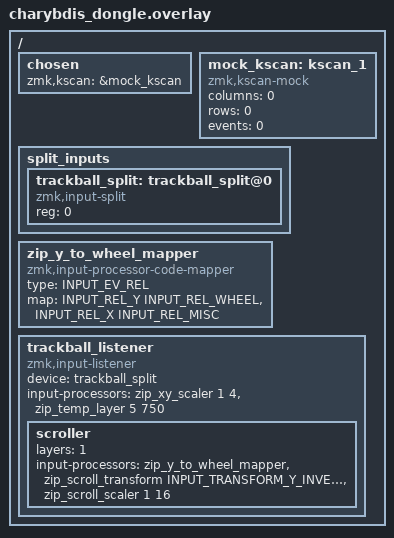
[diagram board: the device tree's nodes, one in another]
#include "charybdis.dtsi"

#include <zephyr/dt-bindings/input/input-event-codes.h>
#include <input/processors.dtsi>
#include <dt-bindings/zmk/input_transform.h>

/ {
    chosen {
        zmk,kscan = &mock_kscan;
    };

    mock_kscan: kscan_1 {
        compatible = "zmk,kscan-mock";
        columns = <0>;
        rows = <0>;
        events = <0>;
    };
};

/* Receiving end of the right half's trackball (see charybdis_right.overlay).
   reg must match the peripheral's zmk,input-split node. */
/ {
    split_inputs {
        #address-cells = <1>;
        #size-cells = <0>;

        trackball_split: trackball_split@0 {
            compatible = "zmk,input-split";
            reg = <0>;
        };
    };
};

/* Scroll mapping matching the old listener: Y -> vertical wheel,
   X -> REL_MISC (ignored by ZMK, so no horizontal scroll and no cursor drift). */
/ {
    zip_y_to_wheel_mapper: zip_y_to_wheel_mapper {
        compatible = "zmk,input-processor-code-mapper";
        #input-processor-cells = <0>;
        type = <INPUT_EV_REL>;
        map = <INPUT_REL_Y INPUT_REL_WHEEL>,
              <INPUT_REL_X INPUT_REL_MISC>;
    };
};

/* Replaces the zmk-input-behavior-listener nodes from charybdis.keymap.
   Layer indices: 0 Base, 1 Lower, 2 Raise, 3 Game, 4 Game ++, 5 Mouse. */
/ {
    trackball_listener: trackball_listener {
        compatible = "zmk,input-listener";
        device = <&trackball_split>;

        /* Default: cursor at 1/4 sensor CPI, auto-mouse layer 5 for 750 ms
           (was scale-divisor 4 + &ib_toggle_layer 5, time-to-live-ms 750). */
        input-processors = <&zip_xy_scaler 1 4>, <&zip_temp_layer 5 750>;

        /* Lower layer: trackball scrolls vertically, inverted, 1/16 scale
           (was trackball_scroll_listener + &ib_wheel_scaler 1 16, y-invert).
           Overrides replace the default processors, so no auto-mouse here. */
        scroller {
            layers = <1>;
            input-processors = <&zip_y_to_wheel_mapper>,
                               <&zip_scroll_transform INPUT_TRANSFORM_Y_INVERT>,
                               <&zip_scroll_scaler 1 16>;
        };

        /* Sniping (was trackball_snipe_listener, which had layers = <> and
           so never activated). To use it, pick a layer and uncomment:
        sniper {
            layers = <N>;
            input-processors = <&zip_xy_scaler 1 12>;
        };
        */
    };
};
